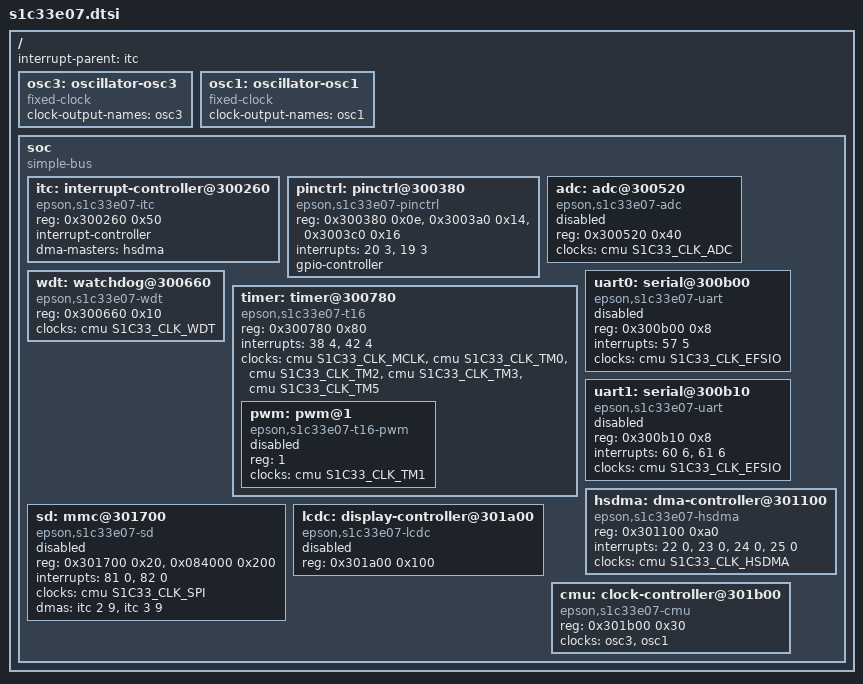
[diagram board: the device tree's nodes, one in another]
// SPDX-License-Identifier: (GPL-2.0-only OR BSD-2-Clause)
/*
 * Epson S1C33E07: the peripherals of the WikiReader's processor that Linux
 * drives.  Interrupts are <vector priority>: the trap vector is the source,
 * and the priority, 1 to 7, is its group's level in the controller.
 */
#include <dt-bindings/clock/epson,s1c33e07-cmu.h>
#include <dt-bindings/gpio/gpio.h>

/ {
	#address-cells = <1>;
	#size-cells = <1>;
	interrupt-parent = <&itc>;

	/* The oscillators' crystals are the board's, which sets their rates. */
	osc3: oscillator-osc3 {
		compatible = "fixed-clock";
		#clock-cells = <0>;
		clock-output-names = "osc3";
	};

	osc1: oscillator-osc1 {
		compatible = "fixed-clock";
		#clock-cells = <0>;
		clock-output-names = "osc1";
	};

	soc {
		compatible = "simple-bus";
		#address-cells = <1>;
		#size-cells = <1>;
		ranges;

		/*
		 * Also the router in front of the HSDMA: a request is
		 * <channel trigger>, and the channel goes to the HSDMA.
		 */
		itc: interrupt-controller@300260 {
			compatible = "epson,s1c33e07-itc";
			reg = <0x300260 0x50>;
			interrupt-controller;
			#interrupt-cells = <2>;
			#dma-cells = <2>;
			dma-masters = <&hsdma>;
		};

		pinctrl: pinctrl@300380 {
			compatible = "epson,s1c33e07-pinctrl";
			reg = <0x300380 0x0e>, <0x3003a0 0x14>, <0x3003c0 0x16>;
			reg-names = "port", "function", "interrupt";
			/* Key input 0 and port input 3, below the timer. */
			interrupts = <20 3>, <19 3>;
			interrupt-names = "key0", "port3";
			gpio-controller;
			#gpio-cells = <2>;
		};

		adc: adc@300520 {
			compatible = "epson,s1c33e07-adc";
			reg = <0x300520 0x40>;
			clocks = <&cmu S1C33_CLK_ADC>;
			#io-channel-cells = <1>;
			status = "disabled";
		};

		wdt: watchdog@300660 {
			compatible = "epson,s1c33e07-wdt";
			reg = <0x300660 0x10>;
			clocks = <&cmu S1C33_CLK_WDT>;
		};

		/*
		 * The 16-bit timers: timer 0 clocks timer 5 for the
		 * clocksource, timer 2 is the clock event and timer 3 the
		 * suspend wake.  The other channels are children, by
		 * channel number.
		 */
		timer: timer@300780 {
			compatible = "epson,s1c33e07-t16";
			reg = <0x300780 0x80>;
			interrupts = <38 4>, <42 4>;
			clocks = <&cmu S1C33_CLK_MCLK>, <&cmu S1C33_CLK_TM0>,
				 <&cmu S1C33_CLK_TM2>, <&cmu S1C33_CLK_TM3>,
				 <&cmu S1C33_CLK_TM5>;
			clock-names = "mclk", "tm0", "tm2", "tm3", "tm5";
			#address-cells = <1>;
			#size-cells = <0>;

			/* Timer 1 as a PWM, on P11. */
			pwm: pwm@1 {
				compatible = "epson,s1c33e07-t16-pwm";
				reg = <1>;
				clocks = <&cmu S1C33_CLK_TM1>;
				#pwm-cells = <3>;
				status = "disabled";
			};
		};

		uart0: serial@300b00 {
			compatible = "epson,s1c33e07-uart";
			reg = <0x300b00 0x8>;
			reg-names = "uart";
			interrupts = <57 5>;
			interrupt-names = "rx";
			clocks = <&cmu S1C33_CLK_EFSIO>;
			status = "disabled";
		};

		uart1: serial@300b10 {
			compatible = "epson,s1c33e07-uart";
			reg = <0x300b10 0x8>;
			reg-names = "uart";
			interrupts = <60 6>, <61 6>;
			interrupt-names = "error", "rx";
			clocks = <&cmu S1C33_CLK_EFSIO>;
			status = "disabled";
		};

		/*
		 * Each channel's end-of-transfer interrupt, polled, not
		 * enabled; its triggers are the interrupt controller's.
		 */
		hsdma: dma-controller@301100 {
			compatible = "epson,s1c33e07-hsdma";
			reg = <0x301100 0xa0>;
			interrupts = <22 0>, <23 0>, <24 0>, <25 0>;
			clocks = <&cmu S1C33_CLK_HSDMA>;
			#dma-cells = <1>;
		};

		/*
		 * The synchronous serial interface as an SD host in SPI mode,
		 * its DMA requests as interrupt causes, polled, not enabled,
		 * and 512 bytes of DST RAM for the all-ones the transmit DMA
		 * sends: internal RAM DMA can read, since the kernel takes
		 * IVRAM into A0 RAM (asm/iram.h).
		 */
		sd: mmc@301700 {
			compatible = "epson,s1c33e07-sd";
			reg = <0x301700 0x20>, <0x084000 0x200>;
			reg-names = "spi", "sram";
			interrupts = <81 0>, <82 0>;
			interrupt-names = "rx", "tx";
			clocks = <&cmu S1C33_CLK_SPI>;
			/* Channel 2 on SPI transmit, 3 on receive: trigger 9. */
			dmas = <&itc 2 9>, <&itc 3 9>;
			dma-names = "tx", "rx";
			status = "disabled";
		};

		/*
		 * The LCD controller.  Its IVRAM is the kernel's A0 RAM
		 * (asm/iram.h), so it scans framebuffers in SDRAM.
		 */
		lcdc: display-controller@301a00 {
			compatible = "epson,s1c33e07-lcdc";
			reg = <0x301a00 0x100>;
			reg-names = "lcdc";
			status = "disabled";
		};

		cmu: clock-controller@301b00 {
			compatible = "epson,s1c33e07-cmu";
			reg = <0x301b00 0x30>;
			clocks = <&osc3>, <&osc1>;
			clock-names = "osc3", "osc1";
			#clock-cells = <1>;
		};
	};
};
